# TC37XPD register map
Vendor: Infineon; Series: ATVMC; File version: 100
CPU: other r0p0, little endian, MPU, FPU, vendor SysTick, 4 interrupt priority bits
Registers are 32-bit, read-write, reset 0x0 unless marked. A register's access mark holds for its fields unless they carry their own. Offsets are from the block's base; [hi:lo] are bit positions; lines under a group give offsets from that group; {n}, {i} and the like mark numbered series; 'fields as' and 'values as' point back to an identical list.

## GTM (part 8 of 13)
Base 0xF0100000
0x9FD04 RESET_CLR wo — Kernel Reset Status Clear Register resetvalue={Application Reset:0x0}
  [0] CLR — Kernel Reset Status Clear. Read always as 0.
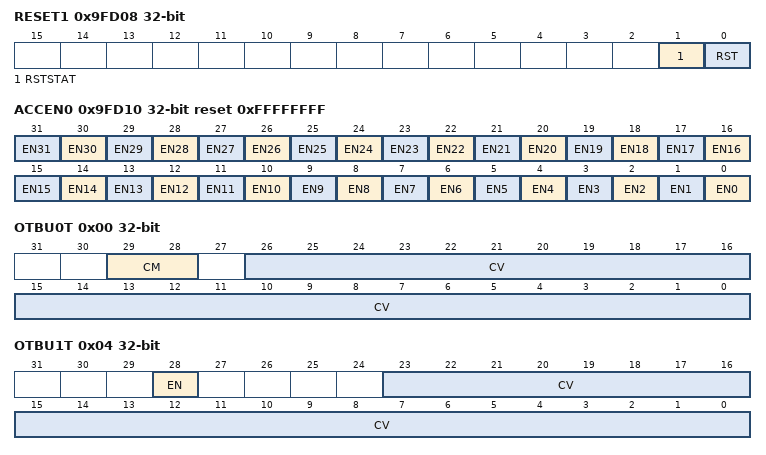
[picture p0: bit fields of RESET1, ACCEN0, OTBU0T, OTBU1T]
0x9FD08 RESET1 access per field — Kernel Reset Register 0 resetvalue={Application Reset:0x0}
  [1] RSTSTAT ro — Kernel Reset Status. This bit indicates whether a kernel reset was executed or not. This bit is set by the BPI FPI after the execution of a kernel reset in the same clock cycle both reset bits. This bit can be cleared by writing with 180 1 180 to the CLR bit in the related RESET CLR register.
  [0] RST rw — Kernel Reset. This reset bit can be used to request for a kernel reset. The kernel reset will be executed if the reset bits of both kernel registers are set. The RST bit will be cleared re set to 180 0 180 by the BPI FPI after the kernel reset was executed.
0x9FD0C RESET2 — Kernel Reset Register 1 resetvalue={Application Reset:0x0}
  [0] RST — Kernel Reset. This reset bit can be used to request a kernel reset. The kernel reset will be executed if the reset bits of both kernel reset registers are set. The RST bit will be cleared re set to 180 0 180 after the kernel reset was executed.
0x9FD10 ACCEN0 reset 0xFFFFFFFF — Access Enable Register 0 resetvalue={Application Reset:0x0FFFFFFFF}
  [n] EN{n} (n=0..31) — Access Enable for Master TAG ID 31. This bit enables write access to the module kernel addresses for transactions with the Master TAG ID n
0x9FD18 OCDS group
  0x00 OTBU0T — OCDS TBU0 Trigger Register resetvalue={Debug Reset:0x0}
    [29:28] CM — Compare Mode
    [26:0] CV — Compare Value. This value is compared to the TBU CH0 BASE register. As long as both match the associated TS16 IOS.MISC bit CROSSREFERENCE is active.
  0x04 OTBU1T — OCDS TBU1 Trigger Register resetvalue={Debug Reset:0x0}
    [28] EN — Enable
    [23:0] CV — Compare Value. This value is compared to the TBU CH1 BASE register. As long as both match the associated TS16 IOS.MISC bit CROSSREFERENCE is active.
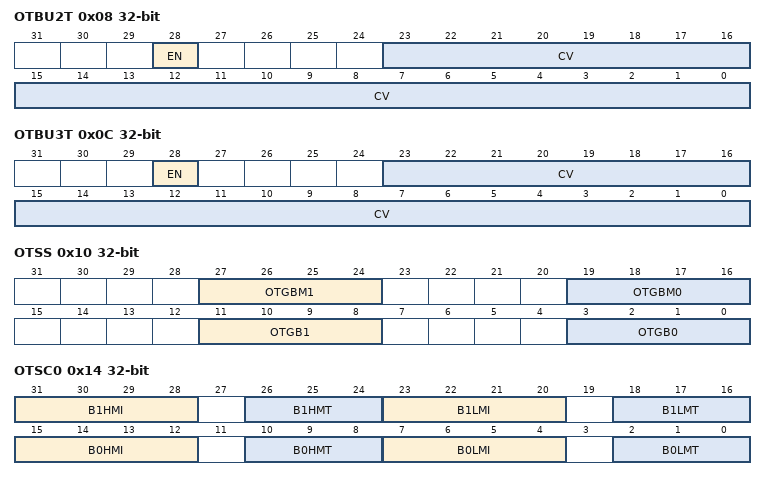
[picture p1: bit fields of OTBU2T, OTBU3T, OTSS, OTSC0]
  0x08 OTBU2T — OCDS TBU2 Trigger Register resetvalue={Debug Reset:0x0}
    [28] EN — Enable
    [23:0] CV — Compare Value. This value is compared to the TBU CH2 BASE register. As long as both match the associated TS16 IOS.MISC bit CROSSREFERENCE is active.
  0x0C OTBU3T — OCDS TBU3 Trigger Register resetvalue={Debug Reset:0x0}
    [28] EN — Enable
    [23:0] CV — Compare Value. This value is compared to the TBU CH3 BASE register. As long as both match the associated TS16 IOS.MISC bit CROSSREFERENCE is active.
  0x10 OTSS — OCDS Trigger Set Select Register resetvalue={Debug Reset:0x0}
    [27:24] OTGBM1 — Trigger Set for OTGBM1
    [19:16] OTGBM0 — Trigger Set for OTGBM0
    [11:8] OTGB1 — Trigger Set for OTGB1
    [3:0] OTGB0 — Trigger Set for OTGB0
  0x14 OTSC0 — OCDS Trigger Set Control 0 Register resetvalue={Debug Reset:0x0}
    [31:28] B1HMI — OTGB1 TS16 IOS High Byte Module Instance. Index of the module instance. Index starts with 0 the max. value depends on GTM configuration and module type. For SPE signals there is a specific mapping CROSSREFERENCE . For MISC signals this index is ignored.
    [26:24] B1HMT — OTGB1 TS16 IOS High Byte Module Type
    [23:20] B1LMI — OTGB1 TS16 IOS Low Byte Module Instance. Index of the module instance. Index starts with 0 the max. value depends on GTM configuration and module type. For SPE signals there is a specific mapping CROSSREFERENCE . For MISC signals this index is ignored.
    [18:16] B1LMT — OTGB1 TS16 IOS Low Byte Module Type
    [15:12] B0HMI — OTGB0 TS16 IOS High Byte Module Instance. Index of the module instance. Index starts with 0 the max. value depends on GTM configuration and module type. For SPE signals there is a specific mapping CROSSREFERENCE . For MISC signals this index is ignored.
    [10:8] B0HMT — OTGB0 TS16 IOS High Byte Module Type
    [7:4] B0LMI — OTGB0 TS16 IOS Low Byte Module Instance. Index of the module instance. Index starts with 0 the max. value depends on GTM configuration and module type. For SPE signals there is a specific mapping CROSSREFERENCE . For MISC signals this index is ignored.
    [2:0] B0LMT — OTGB0 TS16 IOS Low Byte Module Type
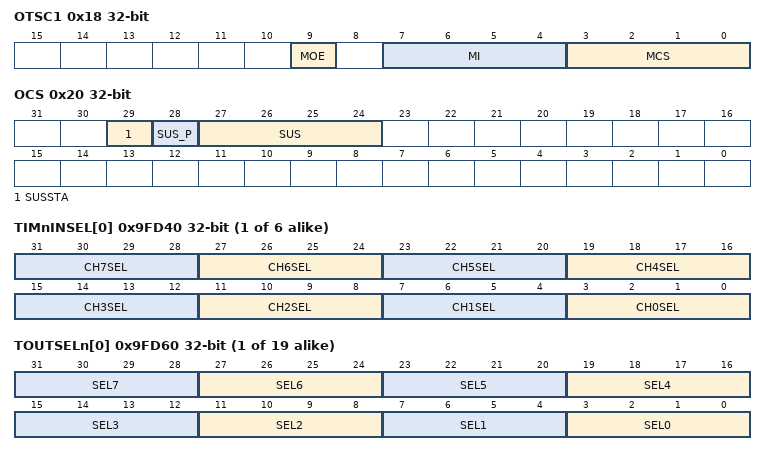
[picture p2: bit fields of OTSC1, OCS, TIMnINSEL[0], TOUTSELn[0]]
  0x18 OTSC1 — OCDS Trigger Set Control 1 Register resetvalue={Debug Reset:0x0}
    [9] MOE — MCS Opcode Trace Enable. Required by TS32 MCD.
    [7:4] MI — MCS Instance. Required by TS32 MCA and TS32 MCD. Index of the MCS instance. Index starts with 0 the max. value depends on the GTM configuration.
    [3:0] MCS — MCS Channel Selection. Required by TS32 MCA and TS32 MCD.
  0x1C ODA — OCDS Debug Access Register resetvalue={Debug Reset:0x0}
    [1:0] DRAC — Debug Read Access Control. Controls Debug Read Access DRA of registers with DRA behavior.
  0x20 OCS access per field — OCDS Control and Status resetvalue={Debug Reset:0x0}
    [29] SUSSTA ro — Suspend State
    [28] SUS_P wo — SUS Write Protection. SUS is only written when SUS P is 1 otherwise it remains unchanged. Read as 0.
    [27:24] SUS rw — OCDS Suspend Control. Controls the sensitivity to the suspend signal coming from the OCDS Trigger Switch OTGS
{0x9FD40+4i} TIMnINSEL[{i}] (i=0..5) — TIM0 Input Select Register resetvalue={Application Reset:0x0}
  [4n+3:4n] CH{n}SEL (n=0..7) — TIM Channel 7 Input Selection. This bit defines which input is connected for TIMn channel x of the GTM. The input is either derived from a port pad or from an on chip module.
{0x9FD60+4i} TOUTSELn[{i}] (i=0..18) — Timer Output Select Register resetvalue={Application Reset:0x0}
  [4n+3:4n] SEL{n} (n=0..7) — TOUT n 8 7 Output Selection. This bit field defines which timer output is connected as TOUT n 8 x . The mapping is defined in the specific appendix. If TOUT n 8 x is not defined in the specific appendix this bit field has to be treated as reserved 0 TOUT not routed to any ports . SELx values not explicitly defined here are equivalent to the last defined SELx setting.
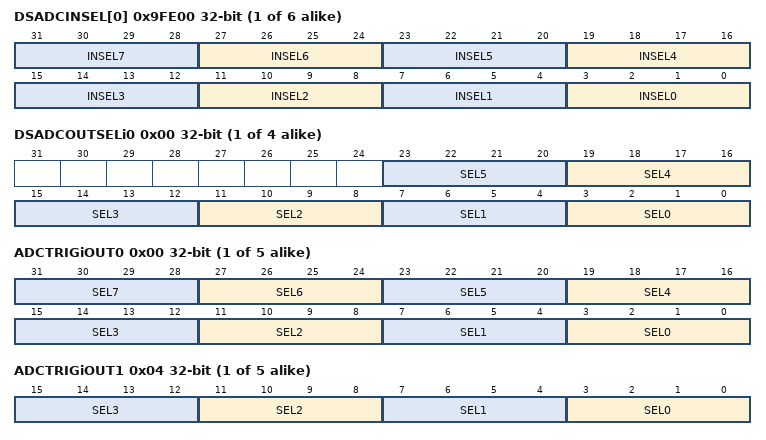
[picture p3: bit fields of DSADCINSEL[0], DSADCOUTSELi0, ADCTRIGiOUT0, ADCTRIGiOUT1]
{0x9FE00+4i} DSADCINSEL[{i}] (i=0..5) — DSADC Input Select i Register resetvalue={Application Reset:0x0}
  [4n+3:4n] INSEL{n} (n=0..7) — In Selection for DSADCn GTM connection. This bit field defines which DSADCn output is connected if the channel input mux is configured as DSADC input for TIMi channel j.
{0x9FE20+8i} DSADC[{i}] (i=0..3) group
  0x00 DSADCOUTSELi0 — DSADC Output Select i0 Register resetvalue={Application Reset:0x0}
    [4n+3:4n] SEL{n} (n=0..5) — Output Selection for DSADC7 GTM connection. This bit field defines which TOM ATOM channel output is used as DSADCx trigger i.
{0x9FE40+8i} ADCTRIG[{i}] (i=0..4) group
  0x00 ADCTRIGiOUT0 — ADC Trigger 0 Output Select 0 Register resetvalue={Application Reset:0x0}
    [4n+3:4n] SEL{n} (n=0..7) — Output Selection for GTM to ADC7 connection. This bit field defines which TOM ATOM channel output is used as ADCx trigger i. The decoding is defined in the specific appendix depending on the ADC.
  0x04 ADCTRIGiOUT1 — ADC Trigger 0 Output Select 1 Register resetvalue={Application Reset:0x0}
    [4n+3:4n] SEL{n} (n=0..3) — Output Selection for GTM to ADC3 connection. This bit field defines which TOM ATOM channel output is used as ADCx 8 trigger i. Decoding is defined in the specific appendix.
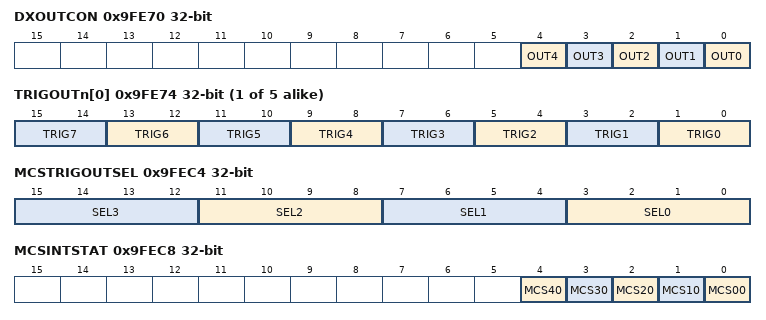
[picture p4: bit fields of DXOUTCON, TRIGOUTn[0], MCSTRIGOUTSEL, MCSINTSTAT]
0x9FE70 DXOUTCON — Data Exchange Output Control Register resetvalue={Application Reset:0x0}
  [n] OUT{n} (n=0..4) — Output 04 Control. This bit defines whether register TRIGOUTx INTOUTx is accessible from the MCS instead of RAM0 or not.
{0x9FE74+4i} TRIGOUTn[{i}] (i=0..4) wo — Trigger Output Register 0 resetvalue={Application Reset:0x0}
  [2n+1:2n] TRIG{n} (n=0..7) — Trigger 7. This bit field defines whether a trigger x request is generated or not. In case of read the value 0x00000000 is returned.
{0x9FE9C+4i} INTOUTn[{i}] (i=0..4) wo — Interrupt Output Register 0 resetvalue={Application Reset:0x0}
  [1:0] INT0 — Interrupt Trigger Request 0. This bit field defines whether an interrupt request 0 is generated or not.In case of read the value 0x00000000 is returned
0x9FEC4 MCSTRIGOUTSEL — Trigger Output Select Register resetvalue={Application Reset:0x0}
  [4n+3:4n] SEL{n} (n=0..3) — Selects which MCS triggers go to FC7BFDAT SEL
0x9FEC8 MCSINTSTAT ro — MCS Interrupt Status Register resetvalue={Application Reset:0x0}
  [4] MCS40 — MCS4 RAM0 Interrupt 0 Status Flag. The requested interrupt is SRC GTMMCSWn0. This bit is cleared when bit MCSINTCLR.MCSn is set.
  [3] MCS30 — MCS4 RAM0 Interrupt 0 Status Flag. The requested interrupt is SRC GTMMCSWn0. This bit is cleared when bit MCSINTCLR.MCSn is set.
  [2] MCS20 — MCS4 RAM0 Interrupt 0 Status Flag. The requested interrupt is SRC GTMMCSWn0. This bit is cleared when bit MCSINTCLR.MCSn is set.
  [1] MCS10 — MCS4 RAM0 Interrupt 0 Status Flag. The requested interrupt is SRC GTMMCSWn0. This bit is cleared when bit MCSINTCLR.MCSn is set.
  [0] MCS00 — MCS4 RAM0 Interrupt 0 Status Flag. The requested interrupt is SRC GTMMCSWn0. This bit is cleared when bit MCSINTCLR.MCSn is set.
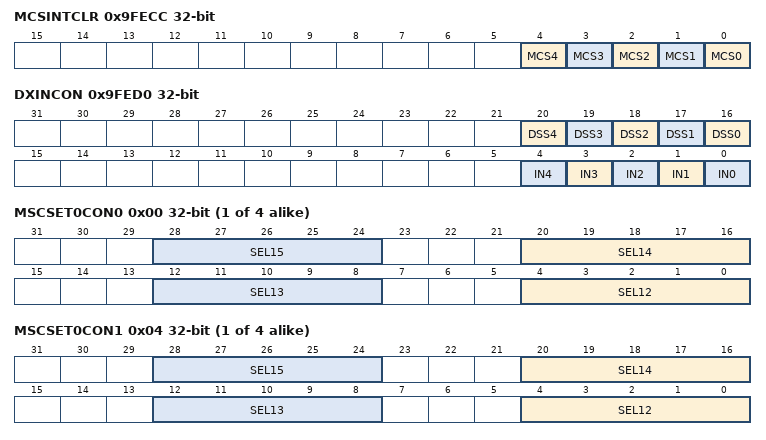
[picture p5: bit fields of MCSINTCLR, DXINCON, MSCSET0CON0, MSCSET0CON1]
0x9FECC MCSINTCLR wo — MCS Interrupt Clear Register resetvalue={Application Reset:0x0}
  [n] MCS{n} (n=0..4) — MCSn RAM0 Interrupt 0 Status Clear Bit. This bit is always read as zero.
0x9FED0 DXINCON — Data Exchange Input Control Register resetvalue={Application Reset:0x0}
  [n+16] DSS{n} (n=0..4) — Data Source Select 04 Control. This bit defines whether the 12 LSB of the read operation directed to register DATAIN0x deliver the register content or the state of 12 inputs.
  [n] IN{n} (n=0..4) — Input 04 Control. This bit defines whether register DATAINx is read from the MCS instead of RAM0 or not.
{0x9FED4+4i} DATAINn[{i}] (i=0..4) — Data Input 0 Register resetvalue={Application Reset:0x0}
  [31:0] DATA — Data. This bit field holds the data for the RAM0 replacement.
0x9FF00 MSC group
  {0x0+4j} SET[{j}] (j=0..3) group
    0x00 MSCSET0CON0 — MSC Set 0 Control 3 Register resetvalue={Application Reset:0x0}
      [8n-92:8n-96] SEL{n} (n=12..15) — Set 0 15 Input Selection. This bit field defines the GTM timer source configured as Set i signal k out. Decoding is defined in the specific appendix.
    0x04 MSCSET0CON1 — MSC Set 0 Control 3 Register resetvalue={Application Reset:0x0}
      fields as MSC.SET[0].MSCSET0CON0
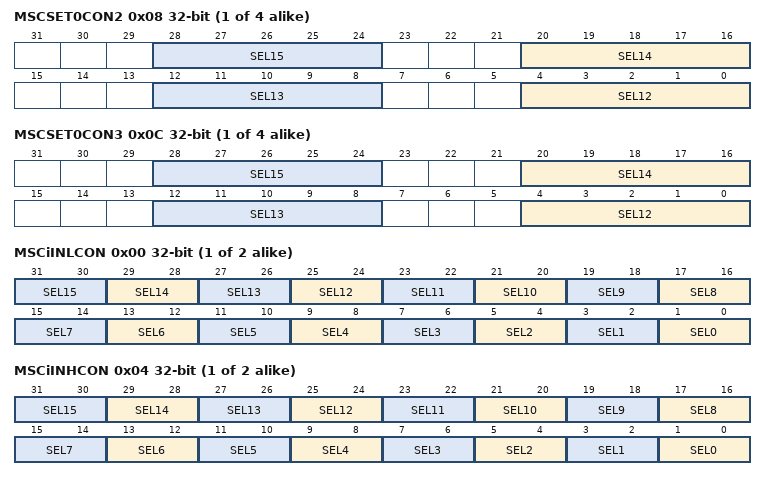
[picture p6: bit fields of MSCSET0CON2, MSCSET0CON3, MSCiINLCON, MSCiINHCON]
    0x08 MSCSET0CON2 — MSC Set 0 Control 3 Register resetvalue={Application Reset:0x0}
      fields as MSC.SET[0].MSCSET0CON0
    0x0C MSCSET0CON3 — MSC Set 0 Control 3 Register resetvalue={Application Reset:0x0}
      fields as MSC.SET[0].MSCSET0CON0
  {0x90+0xC*j} MSCq[{j}] (j=0..1) group
    0x00 MSCiINLCON — MSC0 Input Low Control Register resetvalue={Application Reset:0x0}
      [2n+1:2n] SEL{n} (n=0..15) — GTM MSCq Low 15 Output Selection. GTM output gtm mscqltinl x is controlled by the timer output.
    0x04 MSCiINHCON — MSC0 Input High Control Register resetvalue={Application Reset:0x0}
      [2n+1:2n] SEL{n} (n=0..15) — GTM MSCq High 15 Output Selection. GTM output gtm mscqaltinh x is controlled by the timer output.
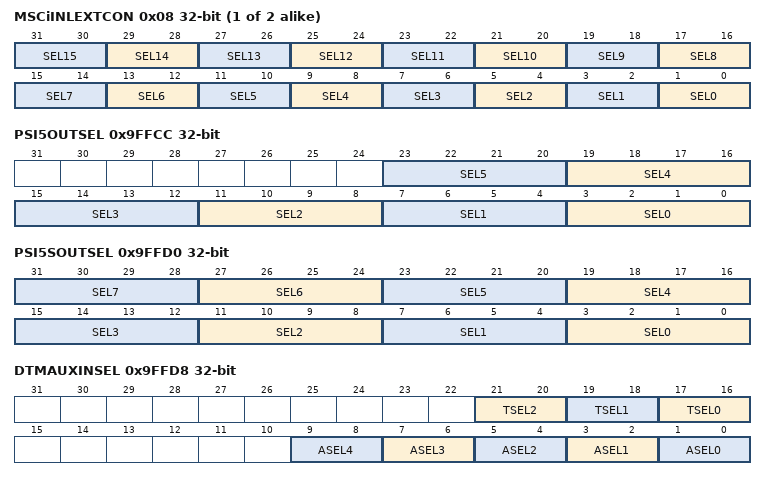
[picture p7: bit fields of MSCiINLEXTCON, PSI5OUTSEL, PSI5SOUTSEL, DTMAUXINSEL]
    0x08 MSCiINLEXTCON — MSC0 Input Low Extended Control Register resetvalue={Application Reset:0x0}
      [2n+1:2n] SEL{n} (n=0..15) — GTM MSCq LowExtended 15 Output Selection. GTM output gtm mscqaltinext x is controlled by the timer output.
0x9FFCC PSI5OUTSEL — PSI5 Output Select Register resetvalue={Application Reset:0x0}
  [4n+3:4n] SEL{n} (n=0..5) — Output Selection for GTM to PSI55 connection. This bit field defines which TOM ATOM channel output is used as PSI5 trigger x. Decoding is defined in the specific appendix.
0x9FFD0 PSI5SOUTSEL — PSI5 S Output Select Register resetvalue={Application Reset:0x0}
  [4n+3:4n] SEL{n} (n=0..7) — Output Selection for GTM to PSI5 S connection. This bit field defines which TOM ATOM channel output is used as PSI5 S trigger x. Decoding is defined in the specific appendix.
0x9FFD4 LCDCDCOUTSEL — LCDCDC Output Select Register resetvalue={Application Reset:0x0}
  [3:0] SEL — Output Selection for GTM to LCDCDC connection. This bit field defines which TOM ATOM channel output is used as LCDCDC signal. Decoding is defined in the specific appendix.
0x9FFD8 DTMAUXINSEL — DTM AUX Input Selection Register resetvalue={Application Reset:0x0}
  [21:20] TSEL2 — CDTM2 DTM0 AUX Input Selection TOMx CH0...3 . This bit field defines which GPIO DSADC EVADC signal is connected to the CDTMx DTM0 AUX input.
  [19:18] TSEL1 — CDTM2 DTM0 AUX Input Selection TOMx CH0...3 . This bit field defines which GPIO DSADC EVADC signal is connected to the CDTMx DTM0 AUX input.
  [17:16] TSEL0 — CDTM2 DTM0 AUX Input Selection TOMx CH0...3 . This bit field defines which GPIO DSADC EVADC signal is connected to the CDTMx DTM0 AUX input.
  [2n+1:2n] ASEL{n} (n=0..4) — CDTM4 DTM4 AUX Input Selection ATOMx CH0...3 . This bit field defines which GPIO DSADC EVADC signal is connected to the CDTMx DTM4 AUX input.
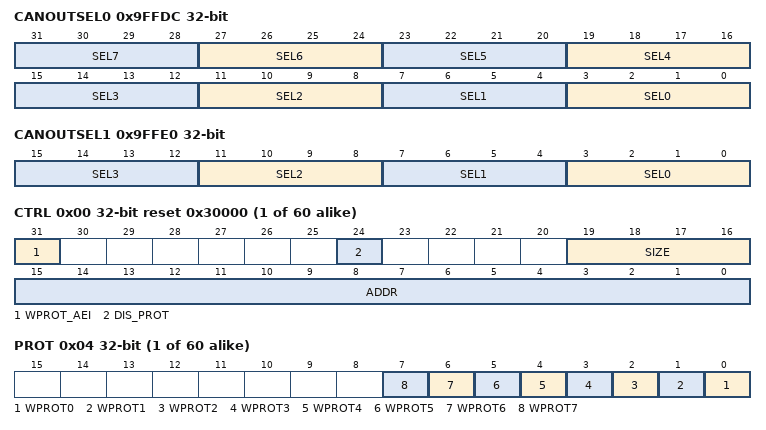
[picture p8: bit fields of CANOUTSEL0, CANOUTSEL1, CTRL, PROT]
0x9FFDC CANOUTSEL0 — CAN0 CAN1 Output Select Register resetvalue={Application Reset:0x0}
  [4n+3:4n] SEL{n} (n=0..7) — Output Selection for GTM to CAN connection 7. This bit field defines which TOM ATOM channel output is used as CAN0 CAN1 node trigger x. Triggers 0 and 1 are also sent to the TTCAN. The decoding is defined in the specific appendix.
0x9FFE0 CANOUTSEL1 — CAN2 Output Select Register resetvalue={Application Reset:0x0}
  [4n+3:4n] SEL{n} (n=0..3) — Output Selection for GTM to CAN connection 3. This bit field defines which TOM ATOM channel output is used as CAN2 node trigger x. The decoding is defined in the specific appendix.
{0xE2000+0x200*i} CCM[{i}] (i=0..5) group
  {0x0+8j} ARP[{j}] (j=0..9) group
    0x00 CTRL reset 0x30000 — CCM0 Address Range Protector 0 Control Register resetvalue={Application Reset:0x30000}
      [31] WPROT_AEI — AEI slave write protection. The address range interval that is protected by this ARP can be calculated as ADDR AND NOT 4 2 SIZE 1 ADDR AND NOT 4 2 SIZE 1 4 2 SIZE 1 assuming a byte wise addressing an unsigned integer representation for the bit fields SIZE and ADDR . NOT and AND are bitwise logical operators. The incrementation interval for neighboring memory locations is always 4. This bit field is only writable if bit field CLS PROT of register CCM i PROT is cleared.
      [24] DIS_PROT — Disable ARP protection. This bit field is only writable if bit field CLS PROT of register CCM i PROT is cleared.
      [19:16] SIZE — Size of ARP. Size of memory range protector z. The actual size of a protected memory range is defined as 2 SIZE address locations whereas the bit field SIZE is interpreted as an unsigned integer number. This bit field is only writable if bit field CLS PROT of register CCM i PROT is cleared.
      [15:0] ADDR — ARP base address. Base address for address range protector z. Only the bits 5 to AAW 1 of this bit field are implemented as registers. The bits AAW to 15 are reserved bits and always read and written as zeros. The bits 0 and 1 are functionally used for the definition of an ARP but they are always read and written as zeros. The actual base address for a protected address range is only defined by the upper AAW SIZE 2 bits bit position 2 SIZE to bit position AAW 1 of bit field ADDR . The lower SIZE 2 bits bit 0 to SIZE 1 are ignored for the address calculation and assumed as zeros. This bit field is only writable if bit field CLS PROT of register CCM i PROT is cleared.
    0x04 PROT — CCM0 Address Range Protector 0 Protection Register resetvalue={Application Reset:0x0}
      [n] WPROT{n} (n=0..7) — Write Protection MCS channel 7
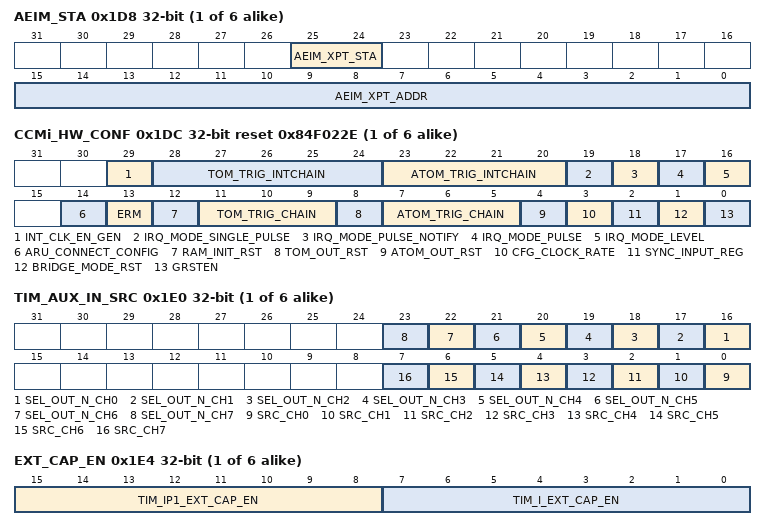
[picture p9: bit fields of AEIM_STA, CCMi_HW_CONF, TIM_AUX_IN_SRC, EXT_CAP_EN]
  0x1D8 AEIM_STA — CCM0 MCS Bus Master Status Register resetvalue={Application Reset:0x0}
    [25:24] AEIM_XPT_STA — AEIM exception status
    [15:0] AEIM_XPT_ADDR — Exception Address. Invalid bus master AEIM address of MCS module.
  0x1DC CCMi_HW_CONF ro reset 0x84F022E — CCM0 Hardware Configuration Register resetvalue={Application Reset:0x084F022E}
    [29] INT_CLK_EN_GEN — Internal clock enable generation
    [28:24] TOM_TRIG_INTCHAIN — TOM internal trigger chain length without synchronization register. It defines after which TOM channel count a synchronization register is introduced into trigger chain. Valid values are 1 to 16. 8 means that in channel 8 of the TOM instances a synchronization register is placed.
    [23:20] ATOM_TRIG_INTCHAIN — ATOM internal trigger chain length without synchronization register. ATOM internal trigger chain length without synchronization register It defines after which ATOM channel count a synchronization register is introduced into trigger chain. Valid values are 1 to 8. 4 means that in channel 4 of the atom instances a synchronization register is placed.
    [19] IRQ_MODE_SINGLE_PULSE
    [18] IRQ_MODE_PULSE_NOTIFY
    [17] IRQ_MODE_PULSE
    [16] IRQ_MODE_LEVEL
    [14] ARU_CONNECT_CONFIG — Defines number of parallel ARU ports
    [13] ERM — Enable RAM1 MSB for available MCS modules. Note The bit reflects the state of the configuration parameter ERM mentioned in the specification of MCFG .
    [12] RAM_INIT_RST — RAM initialization from reset
    [11:9] TOM_TRIG_CHAIN — TOM trigger chain length without synchronization register. It defines after which TOM instance count a synchronization register is introduced into trigger chain after TOM TRIG lt i gt output if instance i and TOM TRIG lt i 1 gt input of instance i 1 . Valid values are 1 to 7. 1 means that after each instance a synchronization register is placed.
    [8] TOM_OUT_RST — TOM OUT reset level. This value represents the TOM output level after reset. The inverse value of this bit is the reset value of bit SL in all TOM channels.
    [7:5] ATOM_TRIG_CHAIN — ATOM trigger chain length without synchronization register. It defines after which ATOM instance count a synchronization register is introduced into trigger chain after ATOM TRIG lt i gt output if instance i and ATOM TRIG lt i 1 gt input of instance i 1 . Valid values are 1 to 7. 1 means that after each instance a synchronization register is placed.
    [4] ATOM_OUT_RST — ATOM OUT reset level. This value represents the ATOM output level after reset. The inverse value of this bit is the reset value of bit SL in all ATOM channels.
    [3] CFG_CLOCK_RATE — Clocks per ARU transfer. This value defines also the availability of configuration bits in register GTM CLS CLK CFG. If CFG CLOCK RATE 0 only the values 00 and 01 are valid for bit fields CLS x x CLK DIV. If CFG CLOCK RATE 1 only the values 00 01 and 10 are valid for bit fields CLS x x CLK DIV.
    [2] SYNC_INPUT_REG — Additional pipelined stage in synchronous bridge mode. Note this register is only relevant if existing for synchronous bridge mode
    [1] BRIDGE_MODE_RST — Bridge mode after reset
    [0] GRSTEN — Global Reset Enable
  0x1E0 TIM_AUX_IN_SRC — CCM0 TIM Module AUX IN Source Selection Register resetvalue={Application Reset:0x0}
    [n+16] SEL_OUT_N_CH{n} (n=0..7) — Use DTM OUT or DTM OUT N signals as AUX IN source of TIM i channel 7. SEL OUT N CH7 Use DTM OUT or DTM OUT N signals as AUX IN source of TIM 0 channel 7
    [n] SRC_CH{n} (n=0..7) — Defines AUX IN source of TIM i channel 7. SRC CH7 Defines AUX IN source of TIM 7 channel 7 SEL OUT N CH7 0 SEL OUT N CH7 1
  0x1E4 EXT_CAP_EN — CCM0 External Capture Trigger Enable Register resetvalue={Application Reset:0x0}
    [15:8] TIM_IP1_EXT_CAP_EN — TIM i 1 EXT CAPTURE signal forwarding enable
    [7:0] TIM_I_EXT_CAP_EN — TIM i EXT CAPTURE signal forwarding enable. Note The trigger event forwarding is possible from TIM i and TIM i 1 to MCS i .
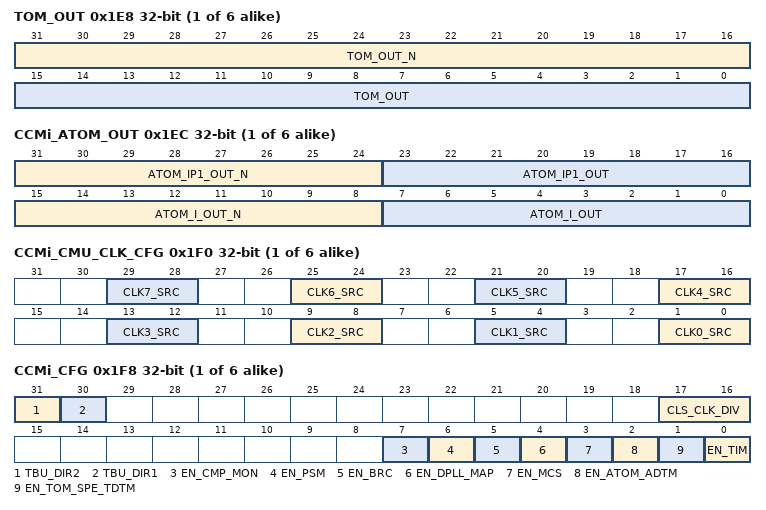
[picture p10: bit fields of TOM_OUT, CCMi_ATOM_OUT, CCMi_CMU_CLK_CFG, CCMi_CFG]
  0x1E8 TOM_OUT ro reset not defined — CCM0 TOM Output Level Register resetvalue={Application Reset:0x0,Application Reset:0x0,Application Reset:0x0,Application Reset:0x0,Application Reset:0x0,Application Reset:0x0,Application Reset:0x0}
    [31:16] TOM_OUT_N — Output level snapshot of TOM i OUT N all channels
    [15:0] TOM_OUT — Output level snapshot of TOM i OUT all channels
  0x1EC CCMi_ATOM_OUT ro — CCM0 ATOM Output Level Register resetvalue={Application Reset:0x0,Application Reset:0x0,Application Reset:0x0,Application Reset:0x0,Application Reset:0x0,Application Reset:0x0,Application Reset:0x0,Application Reset:0x0,Application Reset:0x0,Application Reset:0x0,Application Reset:0x0,Application Reset:0x0,Application Reset:0x0}
    [31:24] ATOM_IP1_OUT_N — Output level snapshot of ATOM i 1 OUT N all channels
    [23:16] ATOM_IP1_OUT — Output level snapshot of ATOM i 1 OUT all channels
    [15:8] ATOM_I_OUT_N — Output level snapshot of ATOM i OUT N all channels
    [7:0] ATOM_I_OUT — Output level snapshot of ATOM i OUT all channels
  0x1F0 CCMi_CMU_CLK_CFG — CCM0 CMU Clock Configuration Register resetvalue={Application Reset:0x0}
    [4n+1:4n] CLK{n}_SRC (n=0..7) — Clock 7 source signal selector
  0x1F4 CCMi_CMU_FXCLK_CFG — CCM0 CMU Fixed Clock Configuration Register resetvalue={Application Reset:0x0}
    [3:0] FXCLK0_SRC — Fixed clock 0 source signal selector. Bit field values that are not mentioned above are reserved. These bits are only writable if bit field CLS PROT of register CCM i PROT is cleared.
  0x1F8 CCMi_CFG access per field reset not defined — CCM0 Configuration Register resetvalue={Application Reset:0x2007F,Application Reset:0x2008F,Application Reset:0x2000F,Application Reset:0x2000D,Application Reset:0x2000D,Application Reset:0x20005,Application Reset:0x2000D,Application Reset:0x2000D,Application Reset:0x2000C,Application Reset:0x2000C,Application Reset:0x20004,Application Reset:0x20004,Application Reset:0x0}
    [31] TBU_DIR2 ro — DIR2 input signal of module TBU
    [30] TBU_DIR1 ro — DIR1 input signal of module TBU
    [17:16] CLS_CLK_DIV ro — Cluster Clock Divider. The value of this bit field mirrors the bit field CLS i CLK DIV of register GTM CLS CLK CFG whereas i equals the cluster index.
    [7] EN_CMP_MON rw — Enable CMP and MON. This bit is only writable if bit field CLS PROT of register CCM i PROT is cleared.
    [6] EN_PSM rw — Enable PSM. This bit is only writable if bit field CLS PROT of register CCM i PROT is cleared.
    [5] EN_BRC rw — Enable BRC. This bit is only writable if bit field CLS PROT of register CCM i PROT is cleared.
    [4] EN_DPLL_MAP rw — Enable DPLL and MAP. This bit is only writable if bit field CLS PROT of register CCM i PROT is cleared.
    [3] EN_MCS rw — Enable MCS. This bit is only writable if bit field CLS PROT of register CCM i PROT is cleared.
    [2] EN_ATOM_ADTM rw — Enable ATOM and ADTM. This bit is only writable if bit field CLS PROT of register CCM i PROT is cleared.
    [1] EN_TOM_SPE_TDTM rw — Enable TOM SPE and TDTM. This bit is only writable if bit field CLS PROT of register CCM i PROT is cleared.
    [0] EN_TIM rw — Enable TIM. This bit is only writable if bit field CLS PROT of register CCM i PROT is cleared.
  0x1FC CCMi_PROT reset 0x1 — CCM0 Protection Register resetvalue={Application Reset:0x1}
    [0] CLS_PROT — Cluster Protection
